# pll_sharing_secure register map
Vendor: Texas Instruments
Peripheral module from a debugger description file (folder CC35X1E).
Registers are 32-bit, access per field, reset 0x0 unless marked. A register's access mark holds for its fields unless they carry their own. Offsets are as the file gives them; lines under a group give offsets from that group; [hi:lo] are bit positions; {n}, {i} and the like mark numbered series; 'fields as' and 'values as' point back to an identical list; <NAME> marks a mode.

## pll_sharing_secure
0x00 pllsh_wcs_pll_m reset 0x140A0 — WCS PLL M divider configuration for WCS PLL - primary reference
  [8:0] VAL rw — In all modes value should be 160
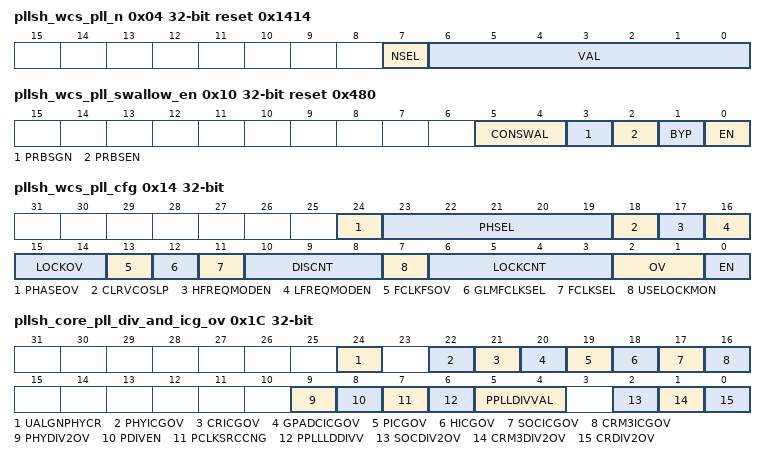
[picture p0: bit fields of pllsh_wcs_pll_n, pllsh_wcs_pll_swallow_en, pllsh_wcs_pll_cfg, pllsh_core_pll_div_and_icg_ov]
0x04 pllsh_wcs_pll_n reset 0x1414 (reset mask 0xFFFFFF7F) — WCS PLL N pre divider configuration for WCS PLL - primary reference
  [7] NSEL rw — N SELECTOR '1' - use MMR N value '0' - use HW auto detection (default)
  [6:0] VAL rw — 10MHz - 5 26MHz - 13 40MHz - 20 52MHz - 26
0x08 pllsh_wcs_pll_q_factor_cfg — WCS Q FACTOR CONFIG swallowing logic configuration for WCS PLL for primary reference clock input - 16 LSB : 16.2MHz - 801 : 16.368MHz - 3751 : 16.8MHz - disabled : 19.2MHz - disabled : 26MHz - disabled : 32.736MHz - 3751 : 33.6MHz - disabled : 38.4MHz - disabled : 52MHz - disabled
  [23:0] SWAL rw — SWALLOWING swallowing logic configuration Q factor
0x0C pllsh_wcs_pll_p_factor_cfg — WCS P FACTOR CONFIG swallowing logic configuration for WCS PLL for primary reference clock input - 16 LSB : P factor 16 LSB : 16.2MHz - 4 : 16.368MHz - 4 : 16.8MHz - disabled : 19.2MHz - disabled : 26MHz - disabled : 32.736MHz - 4 : 33.6MHz - disabled : 38.4MHz - disabled : 52MHz - disabled
  [19:0] SWAL rw — SWALLOWING swallowing logic configuration P factor
0x10 pllsh_wcs_pll_swallow_en reset 0x480 (reset mask 0xFFFFFFC0) — WCS PLL swallowing logic gen cfg
  [5:4] CONSWAL rw — CONSECUTIVE SWALLOWING valid values (1-3) - number of consecutive clock swallows once accumulator reached Q value for WCS PLL
  [3] PRBSGN rw — PRBS GAIN 1: prbs addition is 5 bits to the right of MSB 0: prbs addition is 3 bits to the right of MSB
  [2] PRBSEN rw — enable prbs for adding randomization (jittering)- disable by default
  [1] BYP rw — bypass the swallowing logic
  [0] EN rw — enable the swallowing logic - disable when not using the bypass option
0x14 pllsh_wcs_pll_cfg reset not defined — WCS PLL CONFIG gen cfg for WCS PLL
  [24] PHASEOV rw — PHASE OVERRIDE '1' - Overrideing phase control implementation.
  [23:19] PHSEL rw — PHASE SELECT the following values should be used: 10MHz - up to decimal 0..31 26MHz - up to decimal 0..11 40MHz - up to decimal 0..7 52MHz - up to decimal 0..5 notes: *delayes are set in 320MHz clk *due to sync issues delay could get +1 of the setting value
  [18] CLRVCOSLP rw — CLEAR VCO DURING SLEEP '1' - during sleep VCO 300-400MHz will be gated '0' - during sleep VCO 300-400MHz will stay high
  [17] HFREQMODEN rw — HIGH FREQUENCY MODE ENABLE connected to WCS PLL HIGHFREQ_MODE_EN input : 0: 300M-500M ICO disabled : 1: 300M-400M/400M-500M ICO enabled : based on CONTROL bits [7:6]
  [16] LFREQMODEN rw — LOW FREQUENCY MODE ENABLE connected to WCS PLL LOWFREQ_MODE_EN input : 0:Normal mode : 1: Divide by 2 the PLL clock out
  [15:14] LOCKOV rw — LOCK OVERRIDE override option for WCS PLL lock indication - should be used when using the override option for PLL enable
  [13] FCLKFSOV rw — FREF CLOCK FUSE OVERRIDE '1' - override the PLL_BYPASS fuse with PLL_BYPASS MMR: mem_pllsh_fref_clk_sel; '0' do not override
  [12] GLMFCLKSEL rw — GLITCH LESS MUX FREF CLOCK SELECT select bypass option to use external clock in case PLL not working
  [11] FCLKSEL rw — FREF CLOCK SELECT select bypass option to use external clock in case PLL not working
  [10:8] DISCNT rw — DISABLE COUNTER time (sclk) from pll request goes low to the time PLL input will go low - keep >= 2
  [7] USELOCKMON rw — USE LOCKMON Do not enable this bit because Analog APLL design might have lock stays '1' even when FREF is dropped to OFF. From safety POV, No DCC is used in Osprey, so having a counter based for PLL assumed Lock is ok for the level of safety required 1: use the PLL lock indication for lock 0: use the timer (mem_pllsh_wcs_pll_lock_cnt) for the lock
  [6:3] LOCKCNT rw — LOCK COUNT time (sclk) from enabling the PLL until valid signal will rise. Default is 14 since the PLL lock can go up to 200us and assuming untrimmed slow clk is 15us we need at least 14 cycles This value can be optimized by half by s/w (Once we have trimmed slow clk)
  [2:1] OV rw — override register for WCS PLL enable
  [0] EN rw — enable like any other IP request
0x18 pllsh_core_pll_en — CORE configuration for PLL Sharing
  [0] PLLEN rw — PLL ENABLE register for Core to enable PLLs according to the type instead of using HW request core_pll_en
0x1C pllsh_core_pll_div_and_icg_ov reset not defined — GENERAL PLL divider configuration
  [24] UALGNPHYCR rw — UNALIGNED PHY TO CORE 1: PHY and core clk will get phase difference
  [22] PHYICGOV rw — PHY ICG OVERRIDE 1: ICG of PLL to PHY is forced enable : 0: ICG is enabled according to elp request and phy_pll_en
  [21] CRICGOV rw — CORE ICG OVERRIDE 1: ICG of PLL to Core is forced enable : 0: ICG is enabled according to elp request and core_pll_en
  [20] GPADCICGOV rw — GPADC ICG OVERRIDE '1' - enable gpadc clk '0' - disable clock
  [19] PICGOV rw — PSCON ICG OVERRIDE Default is 1
  [18] HICGOV rw — HOST ICG OVERRIDE '0' - No Override '1' - Enables HOST CLKs
  [17] SOCICGOV rw — SOC ICG OVERRIDE '0' - No Override '1' - Enables SOC 80MHz CLK
  [16] CRM3ICGOV rw — CORE M3 ICG OVERRIDE '0' - No Override '1' - Enables CORE M3 80MHz CLK
  [9] PHYDIV2OV rw — PHY DIVIDER 2 OVERRIDE 1: no division (80MHz clock) : 0: divide by 2 (40MHz clock)
  [8] PDIVEN rw — PSCON DIVIDER ENABLE divider enable. Default is 1. Enabled.
  [7] PCLKSRCCNG rw — PSCON CLOCK SOURCE CHANGE Change divider input clock
  [6] PPLLLDDIVV rw — PSCON PLL LOAD DIVIDER VALUE Load div value indication. Default is 1
  [5:4] PPLLDIVVAL rw — PSCON PLL DIVIDER OVERRIDE 0: no division (80MHz clock) : PSCON div val. Set the PSCON clock period: 0-1us; 1-2us; 2-4us; 3-16us
  [2] SOCDIV2OV rw — SOC DIVIDER 2 OVERRIDE 1: no division (80MHz clock) : 0: divide by 2 (40MHz clock)
  [1] CRM3DIV2OV rw — CORE M3 DIVIDER OVERRIDE 1: no division (80MHz clock) : 0: divide by 2 (40MHz clock)
  [0] CRDIV2OV rw — CORE DIVIDER 2 OVERRIDE 1: no division (80MHz clock) : 0: divide by 2 (40MHz clock)
0x20 pllsh_wcs_pll_ctrl rw reset 0x45100 — WCS CONFIG WCS PLL control input : Refer to WCSPLL spec
  [31:0] CTL — CONTROL
0x24 pllsh_gen_cfg — GENERAL CONFIGURATION PLL sharing module general configurations
  [0] DFTWCSPICGOV rw — DFT WCS PLL ICG OVERRIDE control WCS PLL clock toward test ctrl
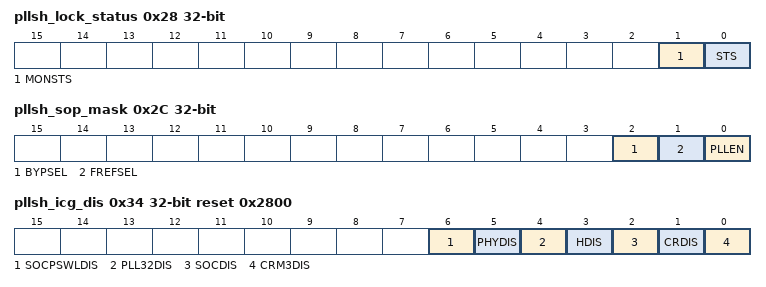
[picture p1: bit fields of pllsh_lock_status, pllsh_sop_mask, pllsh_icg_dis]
0x28 pllsh_lock_status ro — Lock status reg
  [1] MONSTS — LOCK MONITOR STATUS PLL Lock status register
  [0] STS — STATUS PLL Timer for Lock status register in case MEM_USE_LOCKMON = 1 - this indication is similar to LOCKMON_STS in case MEM_USE_LOCKMON = 0 - this indication reflect the Lock Timer (configured by PLL_LOCK_CNT) status (1 means elapsed)
0x2C pllsh_sop_mask — SOP MASK PLL sharing module SOP mask config
  [2] BYPSEL rw — BYPASS SELECTOR SOP mask - Mask SOPs Bypass so PLL Bypass can be can be bypassed by SoC PLL. Default is 0 - "do not mask SOP"
  [1] FREFSEL rw — FREF SELECTOR SOP mask - Mask SOPs Bypass so PLL FREF selected from HFXT over DIO pin. Default is 0 - "do not mask SOP"
  [0] PLLEN rw — PLL ENABLE SOP mask - Mask SOPs Bypass so PLL can be enabled. Default is 0 - "do not mask SOP"
0x30 pllsh_debugss_fast_sel — DEBUGSS
  [0] FSEL rw — FAST SELECTOR Lock status register; clear upon read by S/W
0x34 pllsh_icg_dis reset 0x2800 (reset mask 0xFFFFFF80) — ICG
  [6] SOCPSWLDIS rw — SOC PSWL DISABLE ICG Disable control '1' - disable '0' - enable
  [5] PHYDIS rw — PHY DISABLE ICG Disable control '1' - disable '0' - enable
  [4] PLL32DIS rw — PLL 32 DISABLE ICG control '1' - disable '0' - enable
  [3] HDIS rw — HOST DISABLE ICG Disable control '1' - disable '0' - enable
  [2] SOCDIS rw — SOC DISABLE ICG Disable control '1' - disable '0' - enable
  [1] CRDIS rw — CORE ICS DISABLE ICG Disable control '1' - disable '0' - enable
  [0] CRM3DIS rw — CORE M3 DISABLE ICG Disable control '1' - disable '0' - enable
